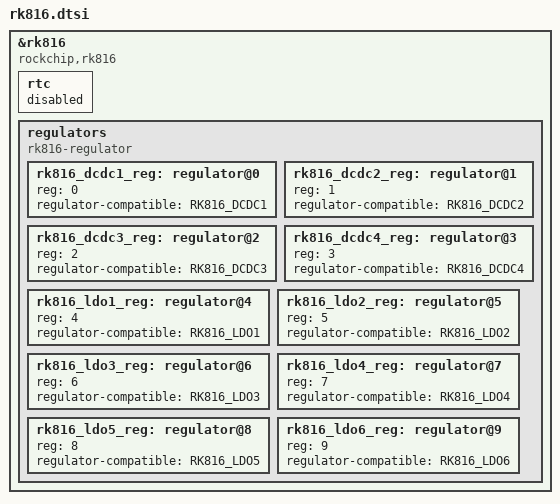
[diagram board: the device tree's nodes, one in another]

&rk816 {
	compatible = "rockchip,rk816";

	rtc {
		status = "disabled";
	};

	regulators {
		#address-cells = <1>;
		#size-cells = <0>;

		compatible = "rk816-regulator";
		rk816_dcdc1_reg: regulator@0 {
			reg = <0>;
			regulator-compatible = "RK816_DCDC1";
		};

		rk816_dcdc2_reg: regulator@1 {
			reg = <1>;
			regulator-compatible = "RK816_DCDC2";
		};

		rk816_dcdc3_reg: regulator@2 {
			reg = <2>;
			regulator-compatible = "RK816_DCDC3";
		};

		rk816_dcdc4_reg: regulator@3 {
			reg = <3>;
			regulator-compatible = "RK816_DCDC4";
		};

		rk816_ldo1_reg: regulator@4 {
			reg = <4>;
			regulator-compatible = "RK816_LDO1";
		};

		rk816_ldo2_reg: regulator@5 {
			reg = <5>;
			regulator-compatible = "RK816_LDO2";
		};

		rk816_ldo3_reg: regulator@6 {
			reg = <6>;
			regulator-compatible = "RK816_LDO3";
		};
       
        rk816_ldo4_reg: regulator@7 {
            reg = <7>; 
            regulator-compatible = "RK816_LDO4";
        };

        rk816_ldo5_reg: regulator@8 {
            reg = <8>;
            regulator-compatible = "RK816_LDO5";
        };

        rk816_ldo6_reg: regulator@9 {
            reg = <9>;
            regulator-compatible = "RK816_LDO6";
        };
	};
};
